# STM32L083xx register map
File version: 1.0
Registers are 32-bit, read-write, reset 0x0 unless marked. A register's access mark holds for its fields unless they carry their own. Offsets are from the block's base; [hi:lo] are bit positions; 'fields as' and 'values as' point back to an identical list.

## RCC — Reset and Clock Control
Base 0x40021000
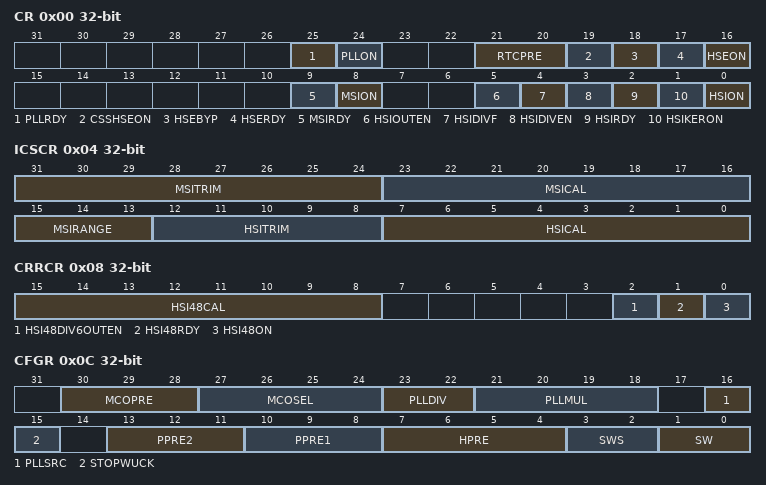
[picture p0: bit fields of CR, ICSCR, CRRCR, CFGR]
0x00 CR — RCC clock control register
  [25] PLLRDY — PLL clock ready flag
  [24] PLLON — PLL enable
  [21:20] RTCPRE — RTC/LCD prescaler [1:0] bits
    0=DIV_2 (HSE is divided by 2 for RTC clock); 1=DIV_4 (HSE is divided by 4 for RTC clock); 2=DIV_8 (HSE is divided by 8 for RTC clock); 3=DIV_16 (HSE is divided by 16 for RTC clock)
  [19] CSSHSEON — HSE Clock Security System enable
  [18] HSEBYP — External High Speed clock Bypass
  [17] HSERDY — External High Speed clock ready flag
  [16] HSEON — External High Speed clock enable
  [9] MSIRDY — Internal Multi Speed clock ready flag
  [8] MSION — Internal Multi Speed clock enable
  [5] HSIOUTEN — Internal High Speed clock out enable
  [4] HSIDIVF — Internal High Speed clock divider flag
  [3] HSIDIVEN — Internal High Speed clock divider enable
  [2] HSIRDY — Internal High Speed clock ready flag
  [1] HSIKERON — Internal High Speed clock enable for some IPs Kernel
  [0] HSION — Internal High Speed clock enable
0x04 ICSCR — RCC Internal clock sources calibration register
  [31:24] MSITRIM — Internal Multi Speed clock trimming
  [23:16] MSICAL — Internal Multi Speed clock Calibration
  [15:13] MSIRANGE — Internal Multi Speed clock Range
    0=MSI = 65.536 KHz; 1=MSI = 131.072 KHz; 2=MSI = 262.144 KHz; 3=MSI = 524.288 KHz; 4=MSI = 1.048 MHz; 5=MSI = 2.097 MHz; 6=MSI = 4.194 MHz
  [12:8] HSITRIM — Internal High Speed clock trimming
  [7:0] HSICAL — Internal High Speed clock Calibration
0x08 CRRCR — RCC Clock recovery RC register
  [15:8] HSI48CAL — HSI 48MHz clock Calibration
  [2] HSI48DIV6OUTEN — HSI 48MHz DIV6 out enable
  [1] HSI48RDY — HSI 48MHz clock ready flag
  [0] HSI48ON — HSI 48MHz clock enable
0x0C CFGR — RCC Clock configuration register
  [30:28] MCOPRE — MCO prescaler
  [27:24] MCOSEL — MCO[3:0] bits (Microcontroller Clock Output)
  [23:22] PLLDIV — PLLDIV[1:0] bits (PLL Output Division)
    1=DIV_2 (PLL clock output = PLLVCO / 2); 2=DIV_3 (PLL clock output = PLLVCO / 3); 3=DIV_4 (PLL clock output = PLLVCO / 4)
  [21:18] PLLMUL — PLLMUL[3:0] bits (PLL multiplication factor)
    0=MUL_3 (PLL input clock * 3); 1=MUL_4 (PLL input clock * 4); 2=MUL_6 (PLL input clock * 6); 3=MUL_8 (PLL input clock * 8); 4=MUL_12 (PLL input clock * 12); 5=MUL_16 (PLL input clock * 16); 6=MUL_24 (PLL input clock * 24); 7=MUL_32 (PLL input clock * 32); 8=MUL_48 (PLL input clock * 48)
  [16] PLLSRC — PLL entry clock source
    0=HSI (HSI clock selected as PLL entry clock source); 1=HSE (HSE clock selected as PLL entry clock source)
  [15] STOPWUCK — Wake Up from Stop Clock selection
    0=MSI (MSI selection after wake-up from STOP); 1=HSI (HSI selection after wake-up from STOP)
  [13:11] PPRE2 — PRE2[2:0] bits (APB2 prescaler)
    0=DIV_1 (HCLK not divided); 4=DIV_2 (HCLK divided by 2); 5=DIV_4 (HCLK divided by 4); 6=DIV_8 (HCLK divided by 8); 7=DIV_16 (HCLK divided by 16)
  [10:8] PPRE1 — PRE1[2:0] bits (APB1 prescaler)
    values as PPRE2
  [7:4] HPRE — HPRE[3:0] bits (AHB prescaler)
    0=DIV_1 (SYSCLK not divided); 8=DIV_2 (SYSCLK divided by 2); 9=DIV_4 (SYSCLK divided by 4); 10=DIV_8 (SYSCLK divided by 8); 11=DIV_16 (SYSCLK divided by 16); 12=DIV_64 (SYSCLK divided by 64); 13=DIV_128 (SYSCLK divided by 128); 14=DIV_256 (SYSCLK divided by 256); 15=DIV_512 (SYSCLK divided by 512)
  [3:2] SWS — SWS[1:0] bits (System Clock Switch Status)
    0=MSI (MSI used as system clock); 1=HSI (HSI used as system clock); 2=HSE (HSE used as system clock); 3=PLL (PLL used as system clock)
  [1:0] SW — SW[1:0] bits (System clock Switch)
    0=MSI (MSI selection as system clock); 1=HSI (HSI selection as system clock); 2=HSE (HSE selection as system clock); 3=PLL (PLL selection as system clock)
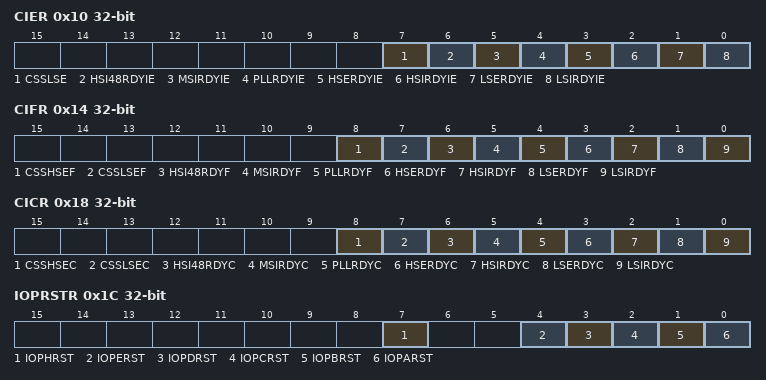
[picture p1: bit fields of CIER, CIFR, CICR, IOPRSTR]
0x10 CIER — RCC Clock interrupt enable register
  [7] CSSLSE — LSE CSS Interrupt Enable
  [6] HSI48RDYIE — HSI48 Ready Interrupt Enable
  [5] MSIRDYIE — MSI Ready Interrupt Enable
  [4] PLLRDYIE — PLL Ready Interrupt Enable
  [3] HSERDYIE — HSE Ready Interrupt Enable
  [2] HSIRDYIE — HSI Ready Interrupt Enable
  [1] LSERDYIE — LSE Ready Interrupt Enable
  [0] LSIRDYIE — LSI Ready Interrupt Enable
0x14 CIFR — RCC Clock interrupt flag register
  [8] CSSHSEF — HSE Clock Security System Interrupt flag
  [7] CSSLSEF — LSE Clock Security System Interrupt flag
  [6] HSI48RDYF — HSI48 Ready Interrupt flag
  [5] MSIRDYF — MSI Ready Interrupt flag
  [4] PLLRDYF — PLL Ready Interrupt flag
  [3] HSERDYF — HSE Ready Interrupt flag
  [2] HSIRDYF — HSI Ready Interrupt flag
  [1] LSERDYF — LSE Ready Interrupt flag
  [0] LSIRDYF — LSI Ready Interrupt flag
0x18 CICR — RCC Clock interrupt clear register
  [8] CSSHSEC — HSE Clock Security System Interrupt Clear
  [7] CSSLSEC — LSE Clock Security System Interrupt Clear
  [6] HSI48RDYC — HSI48 Ready Interrupt Clear
  [5] MSIRDYC — MSI Ready Interrupt Clear
  [4] PLLRDYC — PLL Ready Interrupt Clear
  [3] HSERDYC — HSE Ready Interrupt Clear
  [2] HSIRDYC — HSI Ready Interrupt Clear
  [1] LSERDYC — LSE Ready Interrupt Clear
  [0] LSIRDYC — LSI Ready Interrupt Clear
0x1C IOPRSTR — RCC IO port reset register
  [7] IOPHRST — GPIO port H reset
  [4] IOPERST — GPIO port E reset
  [3] IOPDRST — GPIO port D reset
  [2] IOPCRST — GPIO port C reset
  [1] IOPBRST — GPIO port B reset
  [0] IOPARST — GPIO port A reset
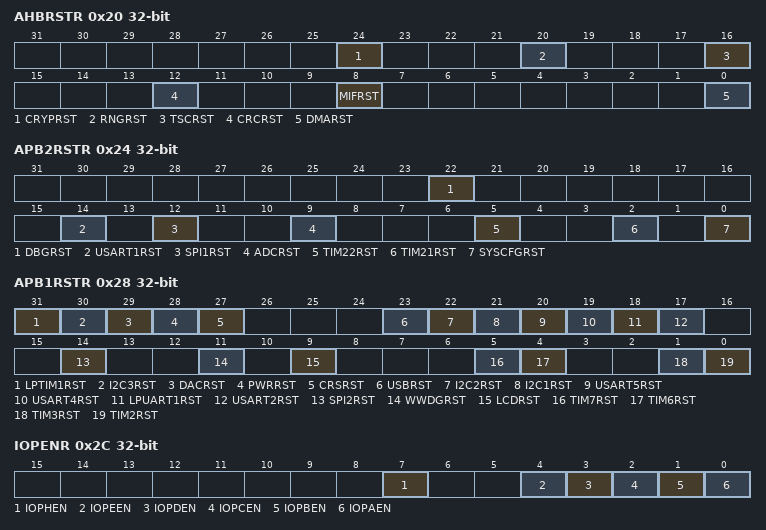
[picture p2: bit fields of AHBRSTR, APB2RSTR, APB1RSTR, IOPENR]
0x20 AHBRSTR — RCC AHB peripheral reset register
  [24] CRYPRST — Crypto reset
  [20] RNGRST — RNG reset
  [16] TSCRST — TSC reset
  [12] CRCRST — CRC reset
  [8] MIFRST — Memory interface reset
  [0] DMARST — DMA1 reset
0x24 APB2RSTR — RCC APB2 peripheral reset register
  [22] DBGRST — DBGMCU reset
  [14] USART1RST — USART1 reset
  [12] SPI1RST — SPI1 reset
  [9] ADCRST — ADC1 reset
  [5] TIM22RST — TIM22 reset
  [2] TIM21RST — TIM21 reset
  [0] SYSCFGRST — SYSCFG reset
0x28 APB1RSTR — RCC APB1 peripheral reset register
  [31] LPTIM1RST — LPTIM1 reset
  [30] I2C3RST — I2C3 reset
  [29] DACRST — DAC reset
  [28] PWRRST — PWR reset
  [27] CRSRST — CRS reset
  [23] USBRST — USB reset
  [22] I2C2RST — I2C 2 reset
  [21] I2C1RST — I2C 1 reset
  [20] USART5RST — USART5 reset
  [19] USART4RST — USART4 reset
  [18] LPUART1RST — LPUART1 reset
  [17] USART2RST — USART 2 reset
  [14] SPI2RST — SPI2 reset
  [11] WWDGRST — Window Watchdog reset
  [9] LCDRST — LCD reset
  [5] TIM7RST — Timer 7 reset
  [4] TIM6RST — Timer 6 reset
  [1] TIM3RST — Timer 3 reset
  [0] TIM2RST — Timer 2 reset
0x2C IOPENR — RCC Clock IO port enable register
  [7] IOPHEN — GPIO port H clock enable
  [4] IOPEEN — GPIO port E clock enable
  [3] IOPDEN — GPIO port D clock enable
  [2] IOPCEN — GPIO port C clock enable
  [1] IOPBEN — GPIO port B clock enable
  [0] IOPAEN — GPIO port A clock enable
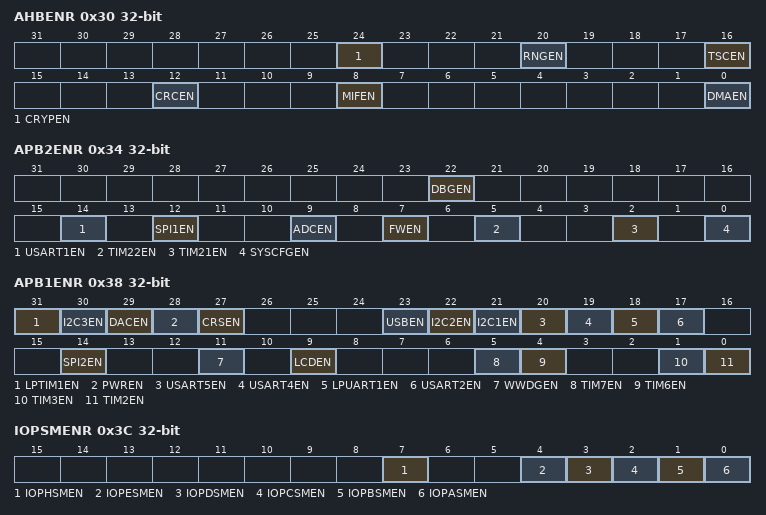
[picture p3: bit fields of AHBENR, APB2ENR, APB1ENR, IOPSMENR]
0x30 AHBENR — RCC AHB peripheral clock enable register
  [24] CRYPEN — Crypto clock enable
  [20] RNGEN — RNG clock enable
  [16] TSCEN — TSC clock enable
  [12] CRCEN — CRC clock enable
  [8] MIFEN — NVM interface clock enable bit
  [0] DMAEN — DMA1 clock enable
0x34 APB2ENR — RCC APB2 peripheral enable register
  [22] DBGEN — DBGMCU clock enable
  [14] USART1EN — USART1 clock enable
  [12] SPI1EN — SPI1 clock enable
  [9] ADCEN — ADC1 clock enable
  [7] FWEN — MiFare Firewall clock enable
  [5] TIM22EN — TIM22 clock enable
  [2] TIM21EN — TIM21 clock enable
  [0] SYSCFGEN — SYSCFG clock enable
0x38 APB1ENR — RCC APB1 peripheral enable register
  [31] LPTIM1EN — LPTIM1 clock enable
  [30] I2C3EN — I2C3 clock enable
  [29] DACEN — DAC clock enable
  [28] PWREN — PWR clock enable
  [27] CRSEN — CRS clock enable
  [23] USBEN — USB clock enable
  [22] I2C2EN — I2C2 clock enable
  [21] I2C1EN — I2C1 clock enable
  [20] USART5EN — USART5 clock enable
  [19] USART4EN — USART4 clock enable
  [18] LPUART1EN — LPUART1 clock enable
  [17] USART2EN — USART2 clock enable
  [14] SPI2EN — SPI2 clock enable
  [11] WWDGEN — Window Watchdog clock enable
  [9] LCDEN — LCD clock enable
  [5] TIM7EN — Timer 7 clock enable
  [4] TIM6EN — Timer 6 clock enable
  [1] TIM3EN — Timer 3 clock enable
  [0] TIM2EN — Timer 2 clock enable
0x3C IOPSMENR — RCC IO port clock enable in sleep mode register
  [7] IOPHSMEN — GPIO port H clock enabled in sleep mode
  [4] IOPESMEN — GPIO port E clock enabled in sleep mode
  [3] IOPDSMEN — GPIO port D clock enabled in sleep mode
  [2] IOPCSMEN — GPIO port C clock enabled in sleep mode
  [1] IOPBSMEN — GPIO port B clock enabled in sleep mode
  [0] IOPASMEN — GPIO port A clock enabled in sleep mode
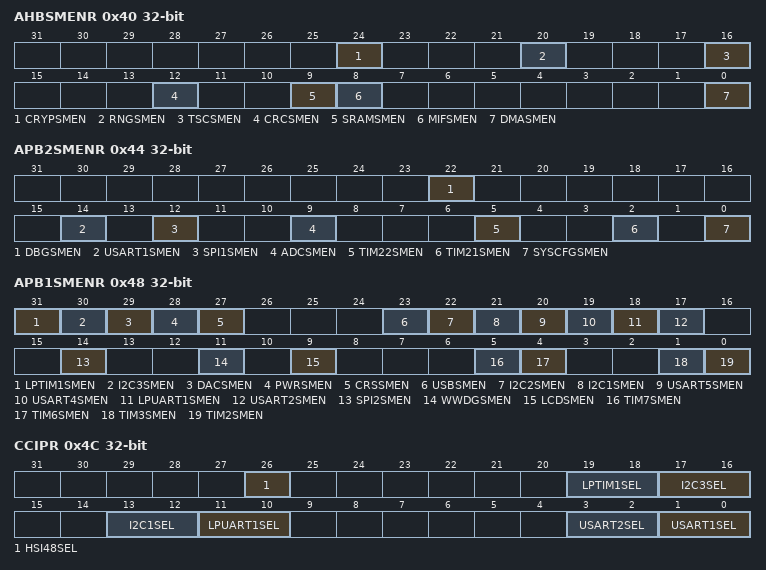
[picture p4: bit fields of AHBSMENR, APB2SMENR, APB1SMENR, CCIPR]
0x40 AHBSMENR — RCC AHB peripheral clock enable in sleep mode register
  [24] CRYPSMEN — Crypto clock enabled in sleep mode
  [20] RNGSMEN — RNG clock enabled in sleep mode
  [16] TSCSMEN — TSC clock enabled in sleep mode
  [12] CRCSMEN — CRC clock enabled in sleep mode
  [9] SRAMSMEN — SRAM clock enabled in sleep mode
  [8] MIFSMEN — NVM interface clock enable during sleep mode
  [0] DMASMEN — DMA1 clock enabled in sleep mode
0x44 APB2SMENR — RCC APB2 peripheral clock enable in sleep mode register
  [22] DBGSMEN — DBGMCU clock enabled in sleep mode
  [14] USART1SMEN — USART1 clock enabled in sleep mode
  [12] SPI1SMEN — SPI1 clock enabled in sleep mode
  [9] ADCSMEN — ADC1 clock enabled in sleep mode
  [5] TIM22SMEN — TIM22 clock enabled in sleep mode
  [2] TIM21SMEN — TIM21 clock enabled in sleep mode
  [0] SYSCFGSMEN — SYSCFG clock enabled in sleep mode
0x48 APB1SMENR — RCC APB1 peripheral clock enable in sleep mode register
  [31] LPTIM1SMEN — LPTIM1 clock enabled in sleep mode
  [30] I2C3SMEN — I2C3 clock enabled in sleep mode
  [29] DACSMEN — DAC clock enabled in sleep mode
  [28] PWRSMEN — PWR clock enabled in sleep mode
  [27] CRSSMEN — CRS clock enabled in sleep mode
  [23] USBSMEN — USB clock enabled in sleep mode
  [22] I2C2SMEN — I2C2 clock enabled in sleep mode
  [21] I2C1SMEN — I2C1 clock enabled in sleep mode
  [20] USART5SMEN — USART5 clock enabled in sleep mode
  [19] USART4SMEN — USART4 clock enabled in sleep mode
  [18] LPUART1SMEN — LPUART1 clock enabled in sleep mode
  [17] USART2SMEN — USART2 clock enabled in sleep mode
  [14] SPI2SMEN — SPI2 clock enabled in sleep mode
  [11] WWDGSMEN — Window Watchdog clock enabled in sleep mode
  [9] LCDSMEN — LCD clock enabled in sleep mode
  [5] TIM7SMEN — Timer 7 clock enabled in sleep mode
  [4] TIM6SMEN — Timer 6 clock enabled in sleep mode
  [1] TIM3SMEN — Timer 3 clock enabled in sleep mode
  [0] TIM2SMEN — Timer 2 clock enabled in sleep mode
0x4C CCIPR — RCC clock configuration register
  [26] HSI48SEL — HSI48 RC clock source selection bit for USB and RNG
    0=PLL (PLL selected as RNG clock); 1=HSI48 (HSI48 selected as RNG clock)
  [19:18] LPTIM1SEL — LPTIM1SEL [1:0] bits
    0=PCLK1 (PCLK1 selected as LPTIM1 clock); 1=LSI (LSI selected as LPTIM1 clock); 2=HSI (HSI selected as LPTIM1 clock); 3=LSE (LSE selected as LPTIM1 clock)
  [17:16] I2C3SEL — I2C3SEL [1:0] bits
  [13:12] I2C1SEL — I2C1SEL [1:0] bits
  [11:10] LPUART1SEL — LPUART1SEL[1:0] bits
    0=PCLK1 (PCLK1 selected as LPUART1 clock); 1=SYSCLK (SYSCLK selected as LPUART1 clock); 2=HSI (HSI selected as LPUART1 clock); 3=LSE (LSE selected as LPUART1 clock)
  [3:2] USART2SEL — USART2SEL[1:0] bits
  [1:0] USART1SEL — USART1SEL[1:0] bits
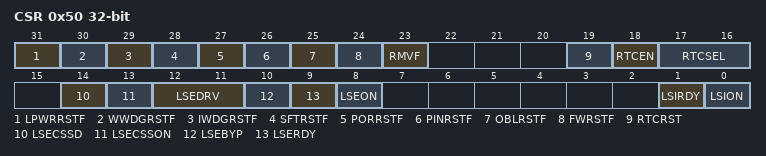
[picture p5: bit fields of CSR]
0x50 CSR — RCC Control/status register
  [31] LPWRRSTF — Low-Power reset flag
  [30] WWDGRSTF — Window watchdog reset flag
  [29] IWDGRSTF — Independent Watchdog reset flag
  [28] SFTRSTF — Software Reset flag
  [27] PORRSTF — POR/PDR reset flag
  [26] PINRSTF — PIN reset flag
  [25] OBLRSTF — OBL reset flag
  [24] FWRSTF — Mifare Firewall reset flag
  [23] RMVF — Remove reset flag
  [19] RTCRST — RTC software reset
  [18] RTCEN — RTC clock enable
  [17:16] RTCSEL — RTCSEL[1:0] bits (RTC clock source selection)
    0=NONE (No clock used as RTC clock); 1=LSE (LSE oscillator clock used as RTC clock); 2=LSI (LSI oscillator clock used as RTC clock); 3=HSE
  [14] LSECSSD — External Low Speed oscillator CSS Detected
  [13] LSECSSON — External Low Speed oscillator CSS Enable
  [12:11] LSEDRV — LSEDRV[1:0] bits (LSE Osc. drive capability)
    0=LOW (Xtal mode lower driving capability); 1=MEDIUMLOW (Xtal mode medium low driving capability); 2=MEDIUMHIGH (Xtal mode medium high driving capability); 3=HIGH (Xtal mode higher driving capability)
  [10] LSEBYP — External Low Speed oscillator Bypass
  [9] LSERDY — External Low Speed oscillator Ready
  [8] LSEON — External Low Speed oscillator enable
  [1] LSIRDY — Internal Low Speed oscillator Ready
  [0] LSION — Internal Low Speed oscillator enable
